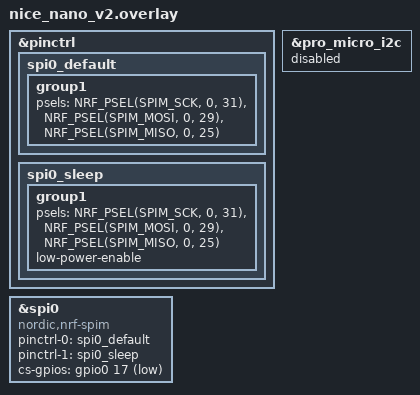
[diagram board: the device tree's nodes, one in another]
/*
 * Copyright (c) 2022 The ZMK Contributors
 *
 * SPDX-License-Identifier: MIT
 */

&pinctrl {
    spi0_default: spi0_default {
        group1 {
            psels = <NRF_PSEL(SPIM_SCK, 0, 31)>,  
                <NRF_PSEL(SPIM_MOSI, 0, 29)>,     
                <NRF_PSEL(SPIM_MISO, 0, 25)>;     
        };
    };
    spi0_sleep: spi0_sleep {
        group1 {
            psels = <NRF_PSEL(SPIM_SCK, 0, 31)>,  
                <NRF_PSEL(SPIM_MOSI, 0, 29)>,     
                <NRF_PSEL(SPIM_MISO, 0, 25)>;     
            low-power-enable;
        };
    };
};

nice_view_spi: &spi0 {
    compatible = "nordic,nrf-spim";
    pinctrl-0 = <&spi0_default>;
    pinctrl-1 = <&spi0_sleep>;
    pinctrl-names = "default", "sleep";
    
    // Changed from pro_micro 1 to gpio0 17
    cs-gpios = <&gpio0 17 GPIO_ACTIVE_LOW>;
}; 

&pro_micro_i2c {
    status = "disabled";
};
